# ESP32C5_RADIO register map
Vendor: Espressif; Series: ESP32-C5; File version: 0.1
Registers are 32-bit, read-write, no defined reset value unless marked. A register's access mark holds for its fields unless they carry their own. Offsets are from the block's base; [hi:lo] are bit positions; 'fields as' and 'values as' point back to an identical list.

## MODEM_WIFI_MAC_POWER_OBSERVED — Sparse source-qualified word views in the existing owned MMIO aperture; individual meanings and side effects remain unknown.
Base 0x600AD800
0x00 WORD_0000_OPAQUE ro — Opaque: meaning not established. Aligned 32-bit bus view explicitly addressed by the cited vendor source. No reset or hardware write effect is established.
  [31:0] BITS_0_31_OPAQUE — Opaque: meaning not established. Observed source use; the individual hardware meaning is unknown.
0x0C WORD_000C_OPAQUE ro — Opaque: meaning not established. Aligned 32-bit bus view explicitly addressed by the cited vendor source. No reset or hardware write effect is established.
  [0] BIT_0_OPAQUE — Opaque: meaning not established. Observed source use; the individual hardware meaning is unknown.
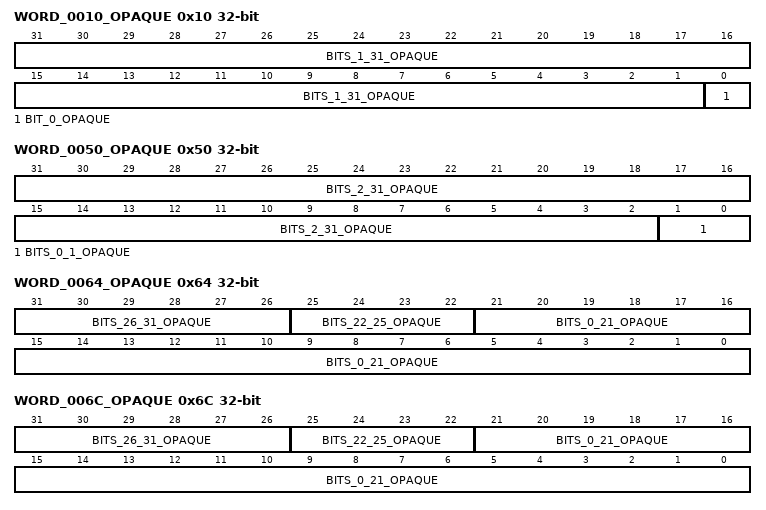
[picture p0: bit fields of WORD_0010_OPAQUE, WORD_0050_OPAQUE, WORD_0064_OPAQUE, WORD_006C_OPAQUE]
0x10 WORD_0010_OPAQUE — Opaque: meaning not established. Aligned 32-bit bus view explicitly addressed by the cited vendor source. No reset or hardware write effect is established.
  [31:1] BITS_1_31_OPAQUE — Opaque: meaning not established. Observed source use; the individual hardware meaning is unknown.
  [0] BIT_0_OPAQUE — Opaque: meaning not established. Observed source use; the individual hardware meaning is unknown.
0x2C WORD_002C_OPAQUE — Opaque: meaning not established. Aligned 32-bit bus view explicitly addressed by the cited vendor source. No reset or hardware write effect is established.
  fields as WORD_0000_OPAQUE
0x3C WORD_003C_OPAQUE — Opaque: meaning not established. Aligned 32-bit bus view explicitly addressed by the cited vendor source. No reset or hardware write effect is established.
  fields as WORD_0000_OPAQUE
0x48 WORD_0048_OPAQUE — Opaque: meaning not established. Aligned 32-bit bus view explicitly addressed by the cited vendor source. No reset or hardware write effect is established.
  fields as WORD_0000_OPAQUE
0x50 WORD_0050_OPAQUE ro — Opaque: meaning not established. Aligned 32-bit bus view explicitly addressed by the cited vendor source. No reset or hardware write effect is established.
  [31:2] BITS_2_31_OPAQUE — Opaque: meaning not established. Observed source use; the individual hardware meaning is unknown.
  [1:0] BITS_0_1_OPAQUE — Opaque: meaning not established. Observed source use; the individual hardware meaning is unknown.
0x64 WORD_0064_OPAQUE — Opaque: meaning not established. Aligned 32-bit bus view explicitly addressed by the cited vendor source. No reset or hardware write effect is established.
  [31:26] BITS_26_31_OPAQUE — Opaque: meaning not established. Observed source use; the individual hardware meaning is unknown.
  [25:22] BITS_22_25_OPAQUE — Opaque: meaning not established. Observed source use; the individual hardware meaning is unknown.
  [21:0] BITS_0_21_OPAQUE — Opaque: meaning not established. Observed source use; the individual hardware meaning is unknown.
0x6C WORD_006C_OPAQUE — Opaque: meaning not established. Aligned 32-bit bus view explicitly addressed by the cited vendor source. No reset or hardware write effect is established.
  fields as WORD_0064_OPAQUE
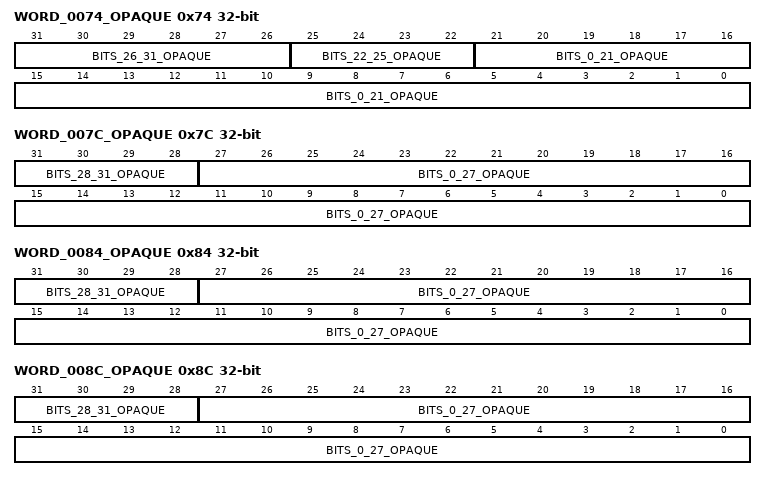
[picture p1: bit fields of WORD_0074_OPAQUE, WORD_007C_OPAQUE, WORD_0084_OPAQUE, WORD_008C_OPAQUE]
0x74 WORD_0074_OPAQUE — Opaque: meaning not established. Aligned 32-bit bus view explicitly addressed by the cited vendor source. No reset or hardware write effect is established.
  fields as WORD_0064_OPAQUE
0x7C WORD_007C_OPAQUE — Opaque: meaning not established. Aligned source-qualified 32-bit bus view in the existing owned aperture. No reset, safe transaction or read safety is established.
  [31:28] BITS_28_31_OPAQUE — Opaque: meaning not established. Observed source use; the individual hardware meaning is unknown.
  [27:0] BITS_0_27_OPAQUE — Opaque: meaning not established. Observed source use; the individual hardware meaning is unknown.
0x80 WORD_0080_OPAQUE — Opaque: meaning not established. Aligned 32-bit bus view explicitly addressed by the cited vendor source. No reset or hardware write effect is established.
  fields as WORD_0000_OPAQUE
0x84 WORD_0084_OPAQUE — Opaque: meaning not established. Aligned source-qualified 32-bit bus view in the existing owned aperture. No reset, safe transaction or read safety is established.
  fields as WORD_007C_OPAQUE
0x88 WORD_0088_OPAQUE — Opaque: meaning not established. Aligned 32-bit bus view explicitly addressed by the cited vendor source. No reset or hardware write effect is established.
  fields as WORD_0000_OPAQUE
0x8C WORD_008C_OPAQUE — Opaque: meaning not established. Aligned source-qualified 32-bit bus view in the existing owned aperture. No reset, safe transaction or read safety is established.
  fields as WORD_007C_OPAQUE
0x90 WORD_0090_OPAQUE — Opaque: meaning not established. Aligned 32-bit bus view explicitly addressed by the cited vendor source. No reset or hardware write effect is established.
  fields as WORD_0000_OPAQUE
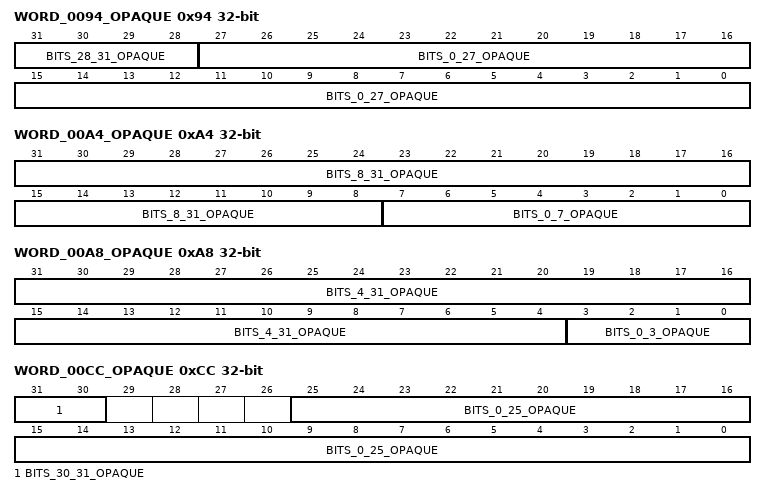
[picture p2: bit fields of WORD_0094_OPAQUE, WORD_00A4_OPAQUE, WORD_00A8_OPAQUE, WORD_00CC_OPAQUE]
0x94 WORD_0094_OPAQUE — Opaque: meaning not established. Aligned source-qualified 32-bit bus view in the existing owned aperture. No reset, safe transaction or read safety is established.
  fields as WORD_007C_OPAQUE
0x98 WORD_0098_OPAQUE — Opaque: meaning not established. Aligned 32-bit bus view explicitly addressed by the cited vendor source. No reset or hardware write effect is established.
  fields as WORD_0000_OPAQUE
0x9C WORD_009C_OPAQUE — Opaque: meaning not established. Aligned 32-bit bus view explicitly addressed by the cited vendor source. No reset or hardware write effect is established.
  fields as WORD_0000_OPAQUE
0xA0 WORD_00A0_OPAQUE — Opaque: meaning not established. Aligned 32-bit bus view explicitly addressed by the cited vendor source. No reset or hardware write effect is established.
  fields as WORD_0000_OPAQUE
0xA4 WORD_00A4_OPAQUE — Opaque: meaning not established. Aligned 32-bit bus view explicitly addressed by the cited vendor source. No reset or hardware write effect is established.
  [31:8] BITS_8_31_OPAQUE — Opaque: meaning not established. Observed source use; the individual hardware meaning is unknown.
  [7:0] BITS_0_7_OPAQUE — Opaque: meaning not established. Observed source use; the individual hardware meaning is unknown.
0xA8 WORD_00A8_OPAQUE — Opaque: meaning not established. Aligned 32-bit bus view explicitly addressed by the cited vendor source. No reset or hardware write effect is established.
  [31:4] BITS_4_31_OPAQUE — Opaque: meaning not established. Observed source use; the individual hardware meaning is unknown.
  [3:0] BITS_0_3_OPAQUE — Opaque: meaning not established. Observed source use; the individual hardware meaning is unknown.
0xAC WORD_00AC_OPAQUE — Opaque: meaning not established. Aligned 32-bit bus view explicitly addressed by the cited vendor source. No reset or hardware write effect is established.
  fields as WORD_0000_OPAQUE
0xCC WORD_00CC_OPAQUE — Opaque: meaning not established. Aligned 32-bit bus view explicitly addressed by the cited vendor source. No reset or hardware write effect is established.
  [31:30] BITS_30_31_OPAQUE — Opaque: meaning not established. Observed source use; the individual hardware meaning is unknown.
  [25:0] BITS_0_25_OPAQUE — Opaque: meaning not established. Observed source use; the individual hardware meaning is unknown.
